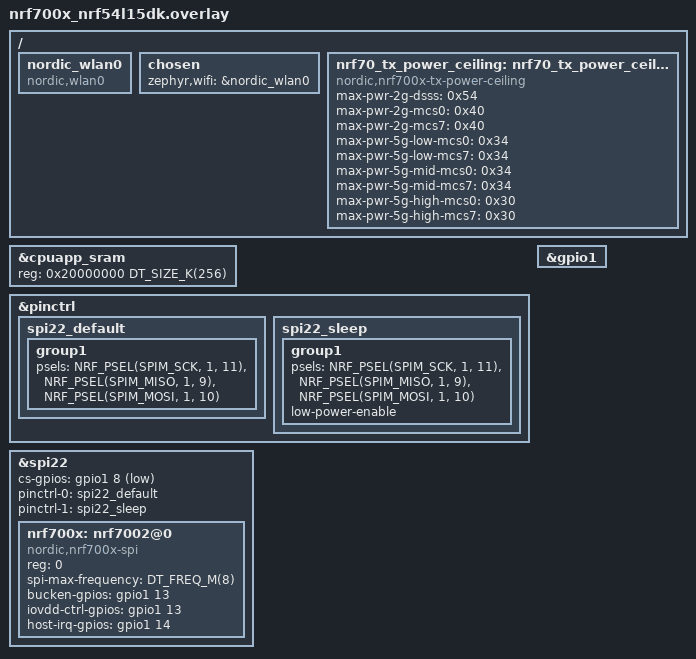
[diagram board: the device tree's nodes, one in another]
/* Copyright (c) 2024 Nordic Semiconductor ASA
 *
 * SPDX-License-Identifier: LicenseRef-Nordic-5-Clause
 */

#include <freq.h>

/ {
	/* Wi-Fi doesn't needs this and it frees up 68K RAM */
	/delete-node/ cpuflpr_sram;
	nordic_wlan0: nordic_wlan0 {
			compatible = "nordic,wlan0";
			status = "okay";
	};

	chosen {
		zephyr,wifi = &nordic_wlan0;
	};

	nrf70_tx_power_ceiling: nrf70_tx_power_ceiling_node {
		status = "okay";
		compatible = "nordic,nrf700x-tx-power-ceiling";
		max-pwr-2g-dsss = <0x54>;
		max-pwr-2g-mcs0 = <0x40>;
		max-pwr-2g-mcs7 = <0x40>;
		max-pwr-5g-low-mcs0 = <0x34>;
		max-pwr-5g-low-mcs7 = <0x34>;
		max-pwr-5g-mid-mcs0 = <0x34>;
		max-pwr-5g-mid-mcs7 = <0x34>;
		max-pwr-5g-high-mcs0 = <0x30>;
		max-pwr-5g-high-mcs7 = <0x30>;
	};
};

&cpuapp_sram {
	reg = <0x20000000 DT_SIZE_K(256)>;
	ranges = <0x0 0x20000000 0x20040000>;
};

&pinctrl {
	spi22_default: spi22_default {
		group1 {
			psels = <NRF_PSEL(SPIM_SCK, 1, 11)>,
				<NRF_PSEL(SPIM_MISO, 1, 9)>,
				<NRF_PSEL(SPIM_MOSI, 1, 10)>;
		};
	};

	spi22_sleep: spi22_sleep {
		group1 {
			psels = <NRF_PSEL(SPIM_SCK, 1, 11)>,
				<NRF_PSEL(SPIM_MISO, 1, 9)>,
				<NRF_PSEL(SPIM_MOSI, 1, 10)>;
			low-power-enable;
		};
	};
};

/* With P1 only SPI20/21/22 are allowed and SPI20 uses same IRQ as UART20 */
&spi22 {
	status = "okay";
	cs-gpios = <&gpio1 8 GPIO_ACTIVE_LOW>;

	pinctrl-0 = <&spi22_default>;
	pinctrl-1 = <&spi22_sleep>;
	pinctrl-names = "default", "sleep";
	nrf700x: nrf7002@0 {
		compatible = "nordic,nrf700x-spi";
		status = "okay";
		reg = <0>;
		spi-max-frequency = <DT_FREQ_M(8)>;
		bucken-gpios = <&gpio1 13 (GPIO_ACTIVE_HIGH | GPIO_PULL_DOWN)>;
		iovdd-ctrl-gpios = <&gpio1 13 (GPIO_ACTIVE_HIGH | GPIO_PULL_DOWN)>;
		host-irq-gpios = <&gpio1 14 GPIO_ACTIVE_HIGH>;
	};
};


&gpio1 {
	status = "okay";
};
